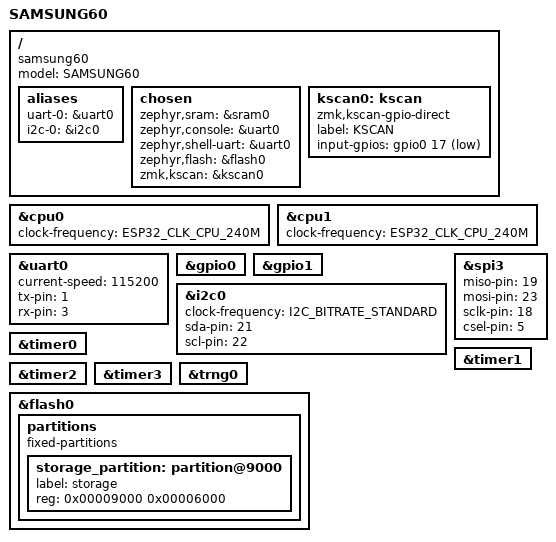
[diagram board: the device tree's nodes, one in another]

/*
 * Copyright (c) 2021 The ZMK Contributors
 *
 * SPDX-License-Identifier: MIT
 */

/dts-v1/;
#include <espressif/esp32.dtsi>
#include <dt-bindings/zmk/matrix_transform.h>

/ {
	model = "SAMSUNG60";
	compatible = "samsung60";
	aliases {
		uart-0 = &uart0;
		i2c-0 = &i2c0;
	};
	chosen {
		// zephyr,code-partition = &code_partition;
		zephyr,sram = &sram0;
		zephyr,console = &uart0;
		zephyr,shell-uart = &uart0;
		zephyr,flash = &flash0;
		zmk,kscan = &kscan0;
	};

	kscan0: kscan {
		compatible = "zmk,kscan-gpio-direct";
		label = "KSCAN";

		input-gpios
		= <&gpio0 17 (GPIO_ACTIVE_LOW | GPIO_PULL_UP)>
		;
	};

	// vbatt {
	// 	compatible = "zmk,battery-voltage-divider";
	// 	label = "BATTERY";
	// 	io-channels = <&adc 2>;
	// 	output-ohms = <2000000>;
	// 	full-ohms = <(2000000 + 820000)>;
	// };
};

&cpu0 {
	clock-frequency = <ESP32_CLK_CPU_240M>;
};

&cpu1 {
	clock-frequency = <ESP32_CLK_CPU_240M>;
};

&uart0 {
	status = "okay";
	current-speed = <115200>;
	tx-pin = <1>;
	rx-pin = <3>;
	// rts-pin = <22>;
	// cts-pin = <19>;
};

// &uart1 {
// 	current-speed = <115200>;
// 	tx-pin = <10>;
// 	rx-pin = <9>;
// 	rts-pin = <11>;
// 	cts-pin = <6>;
// 	hw-flow-control;
// };

// &uart2 {
// 	current-speed = <115200>;
// 	tx-pin = <17>;
// 	rx-pin = <16>;
// 	rts-pin = <7>;
// 	cts-pin = <8>;
// 	hw-flow-control;
// };

&gpio0 {
	status = "okay";
};

&gpio1 {
	status = "okay";
};

&i2c0 {
	status = "okay";
	clock-frequency = <I2C_BITRATE_STANDARD>;
	sda-pin = <21>;
	scl-pin = <22>;
};

// &i2c1 {
// 	clock-frequency = <I2C_BITRATE_STANDARD>;
// 	sda-pin = <18>;
// 	scl-pin = <5>;
// };

// &spi2 {
// 	#address-cells = <1>;
// 	#size-cells = <0>;
// 	status = "okay";
// 	miso-pin = <12>;
// 	mosi-pin = <13>;
// 	sclk-pin = <14>;
// 	csel-pin = <15>;
// };

&spi3 {
	#address-cells = <1>;
	#size-cells = <0>;
	status = "okay";
	miso-pin = <19>;
	mosi-pin = <23>;
	sclk-pin = <18>;
	csel-pin = <5>;
};

&timer0 {
	status = "okay";
};

&timer1 {
	status = "okay";
};

&timer2 {
	status = "okay";
};

&timer3 {
	status = "okay";
};

&trng0 {
	status = "okay";
};
&flash0 {
	status = "okay";
	partitions {
		compatible = "fixed-partitions";
		#address-cells = <1>;
		#size-cells = <1>;

		storage_partition: partition@9000 {
			label = "storage";
			reg = <0x00009000 0x00006000>;
		};
	};
};

